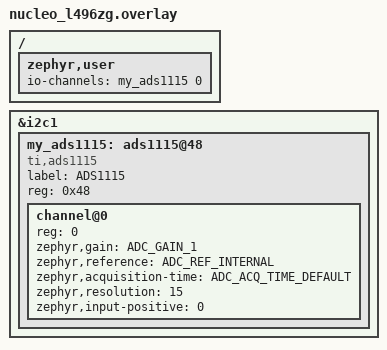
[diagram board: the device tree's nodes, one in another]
#include <zephyr/dt-bindings/adc/adc.h>

/ {
	zephyr,user {
		/* adjust channel number according to pinmux in board.dts */
		io-channels = <&my_ads1115 0>; 
	};
};

&i2c1 {
	my_ads1115: ads1115@48{
		compatible = "ti,ads1115";
		label = "ADS1115";
		status = "okay";
		reg = <0x48>;
		
		#io-channel-cells = <1>;

		#address-cells = <1>;
		#size-cells = <0>;
	
		channel@0{
			reg = <0> ;
			zephyr,gain = "ADC_GAIN_1";
			zephyr,reference = "ADC_REF_INTERNAL";
			zephyr,acquisition-time = <ADC_ACQ_TIME_DEFAULT>;
			zephyr,resolution = <15>;		
		
			zephyr,input-positive = <0>; 
		};			
	};
};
